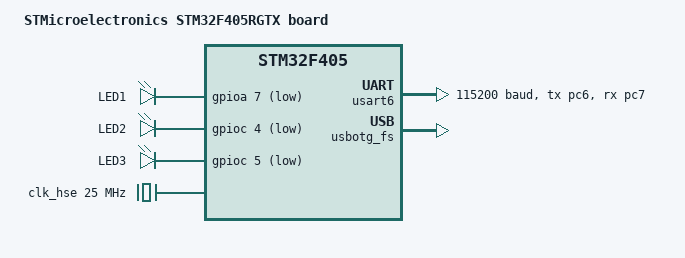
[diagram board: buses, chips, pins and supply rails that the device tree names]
/*
 * Copyright (c) 2017 Linaro Limited
 *
 * SPDX-License-Identifier: Apache-2.0
 */

/dts-v1/;
#include <st/f4/stm32f405Xg.dtsi>
#include <st/f4/stm32f405rgtx-pinctrl.dtsi>

/ {
  model = "STMicroelectronics STM32F405RGTX board";
  compatible = "st,stm32f405";

  chosen {
    // zephyr,console = &usart6;
    // zephyr,shell-uart = &usart6; // for bootloader
    zephyr,sram = &sram0;
    zephyr,flash = &flash0;
    zephyr,ccm = &ccm0;
    // zephyr,can-primary = &can1;
    zephyr,code-partition = &slot0_partition;
  };

  leds {
    compatible = "gpio-leds";
    status_led1: led_1 {
      gpios = <&gpioa 7 GPIO_ACTIVE_LOW>;
      label = "LED1";
    };
    status_led2: led_2 {
        gpios = <&gpioc 4 GPIO_ACTIVE_LOW>;
        label = "LED2";
      };
    status_led3: led_3 {
    gpios = <&gpioc 5 GPIO_ACTIVE_LOW>;
    label = "LED3";
    };
  };

//   gpio_keys {
//     compatible = "gpio-keys";
//     power_ctrl: power_control {
//       gpios = <&gpiob 0 GPIO_ACTIVE_HIGH>;
//       label = "Power Control";
//     };
//     power1: supply_19v {
//       gpios = <&gpioc 9 GPIO_ACTIVE_HIGH>;
//       label = "19v supply";
//     };
//     power2: supply_12v {
//       gpios = <&gpioc 10 GPIO_ACTIVE_LOW>;
//       label = "12v supply";
//     };
//     power3: supply_12vi {
//       gpios = <&gpioc 11 GPIO_ACTIVE_HIGH>;
//       label = "Isolated 12v supply";
//     };
//     power4: supply_5vi {
//       gpios = <&gpioc 12 GPIO_ACTIVE_HIGH>;
//       label = "Isolated 5v supply";
//     };
//   };

//   stm-temp {
//     label = "DIE_TEMP";
//     compatible = "st,stm32-temp";
//     io-channels = <&adc1 18>;
//     status = "okay";
//   };

  aliases {
    led1 = &status_led1;
    led2 = &status_led2;
    led3 = &status_led3;
//     powerctrl = &power_ctrl;
//     supply-19v = &power1;
//     supply-12v = &power2;
//     supply-12vi = &power3;
//     supply-5vi = &power4;
  };
};

// &adc1 {
//   status = "okay";
// };

// &i2c1 {
//   status = "okay";
//   clock-frequency = <I2C_BITRATE_FAST>;
// };

// &spi1 {
//   status = "okay";
// };

// &usart3 {
// //   parity = <2>;
//   pinctrl-0 = <&usart3_tx_pb10 &usart3_rx_pb11>;
//   current-speed = <100000>;
//   status = "okay";
// };

&usart6 {
//   parity = "0";
  pinctrl-0 = <&usart6_tx_pc6 &usart6_rx_pc7>;
  current-speed = <115200>;
  status = "okay";
};

&usbotg_fs {
  status = "okay";
};

// &timers2 {
//   status = "okay";
//   pwm1: pwm1 {
//     compatible = "st,stm32-pwm";
//     pinctrl-0 = <&tim2_ch4_pa3>;
//     st,prescaler = <8399>;
//     #pwm-cells = <3>;
//     label = "Rear Lights PWM";
//   };
//   pwm2: pwm2 {
//     compatible = "st,stm32-pwm";
//     pinctrl-0 = <&tim2_ch2_pa1>;
//     st,prescaler = <8399>;
//     #pwm-cells = <3>;
//     label = "Front Lights PWM";
//   };
// };

&clk_hse {
  hse-bypass;
  clock-frequency = <DT_FREQ_M(25)>; /* STLink 8MHz clock */
  status = "okay";
};

&pll {
  div-m = <25>;
  mul-n = <427>;
  div-p = <2>;
  div-q = <7>;
  clocks = <&clk_hse>;
  status = "okay";
};

&rcc {
  clocks = <&pll>;
  clock-frequency = <DT_FREQ_M(168)>; /* highest value to get a precise USB clock */
  ahb-prescaler = <1>;
  apb1-prescaler = <4>;
  apb2-prescaler = <2>;
};

// &rtc {
//   status = "okay";
// };

// &iwdg {
//   status = "okay";
// };

// &rng {
//   status = "okay";
// };

// &can1 {
//   pinctrl-0 = <&can1_rx_pa11 &can1_tx_pa12>;
//   bus-speed = <500000>;
//   sjw = <1>;
//   prop-seg = <0>;
//   phase-seg1 = <10>;
//   phase-seg2 = <1>;
//   status = "okay";
// };

// &can2 {
//   pinctrl-0 = <&can2_rx_pb12 &can2_tx_pb13>;
//   bus-speed = <1000000>;
//   sjw = <1>;
//   prop-seg = <0>;
//   phase-seg1 = <11>;
//   phase-seg2 = <2>;
//   status = "okay";
// };

&flash0 {
  /*
   * For more information, see:
   * https: //docs.zephyrproject.org/latest/reference/devicetree/index.html#fixed-flash-partitions
   */
  partitions {
    compatible = "fixed-partitions";
    #address-cells = <1>;
    #size-cells = <1>;

    /* 64KB for bootloader */
    boot_partition: partition@0 {
      label = "mcuboot";
      reg = <0x00000000 0x00010000>;
      read-only;
    };

    /* storage: 64KB for settings */
    storage_partition: partition@10000 {
      label = "storage";
      reg = <0x00010000 0x00010000>;
    };

    /* application image slot: 256KB */
    slot0_partition: partition@20000 {
      label = "image-0";
      reg = <0x00020000 0x00040000>;
    };

    /* backup slot: 256KB */
    slot1_partition: partition@60000 {
      label = "image-1";
      reg = <0x00060000 0x00040000>;
    };

    /* swap slot: 128KB */
    scratch_partition: partition@a0000 {
      label = "image-scratch";
      reg = <0x000a0000 0x00020000>;
    };

  };
};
